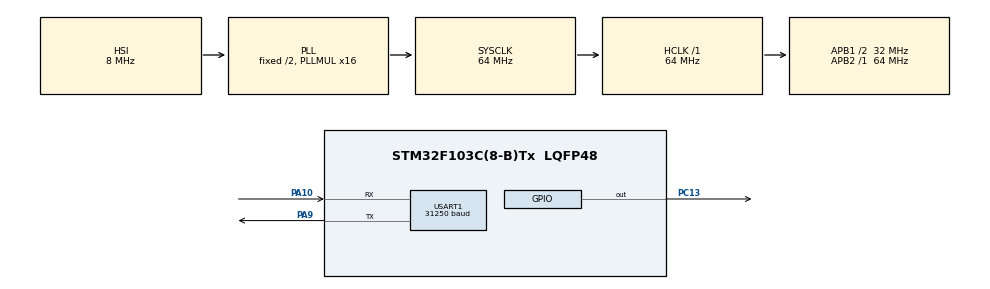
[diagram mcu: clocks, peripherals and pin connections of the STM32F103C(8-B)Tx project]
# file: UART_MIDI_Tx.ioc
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Mcu.Family=STM32F1
Mcu.Name=STM32F103C(8-B)Tx
Mcu.Package=LQFP48
NVIC.PriorityGroup=NVIC_PRIORITYGROUP_4
PA10.Mode=Asynchronous
PA10.Signal=USART1_RX
PA13.Mode=Serial_Wire
PA13.Signal=SYS_JTMS-SWDIO
PA14.Mode=Serial_Wire
PA14.Signal=SYS_JTCK-SWCLK
PA9.Mode=Asynchronous
PA9.Signal=USART1_TX
PC13-TAMPER-RTC.Signal=GPIO_Output
ProjectManager.HeapSize=0x200
ProjectManager.StackSize=0x400
ProjectManager.TargetToolchain=TrueSTUDIO
RCC.AHBFreq_Value=64000000
RCC.APB1CLKDivider=RCC_HCLK_DIV2
RCC.APB1Freq_Value=32000000
RCC.APB1TimFreq_Value=64000000
RCC.APB2Freq_Value=64000000
RCC.APB2TimFreq_Value=64000000
RCC.HCLKFreq_Value=64000000
RCC.PLLMUL=RCC_PLL_MUL16
RCC.SYSCLKFreq_VALUE=64000000
RCC.SYSCLKSource=RCC_SYSCLKSOURCE_PLLCLK
RCC.USBFreq_Value=64000000
USART1.BaudRate=31250
USART1.Mode=MODE_TX
USART1.VirtualMode=VM_ASYNC
board=custom

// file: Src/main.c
/* USER CODE BEGIN Header */
/**
  ******************************************************************************
  * @file           : main.c
  * @brief          : Main program body
  ******************************************************************************
  ** This notice applies to any and all portions of this file
  * that are not between comment pairs USER CODE BEGIN and
  * USER CODE END. Other portions of this file, whether
  * inserted by the user or by software development tools
  * are owned by their respective copyright owners.
  *
  * COPYRIGHT(c) 2019 STMicroelectronics
  *
  * Redistribution and use in source and binary forms, with or without modification,
  * are permitted provided that the following conditions are met:
  *   1. Redistributions of source code must retain the above copyright notice,
  *      this list of conditions and the following disclaimer.
  *   2. Redistributions in binary form must reproduce the above copyright notice,
  *      this list of conditions and the following disclaimer in the documentation
  *      and/or other materials provided with the distribution.
  *   3. Neither the name of STMicroelectronics nor the names of its contributors
  *      may be used to endorse or promote products derived from this software
  *      without specific prior written permission.
  *
  * THIS SOFTWARE IS PROVIDED BY THE COPYRIGHT HOLDERS AND CONTRIBUTORS "AS IS"
  * AND ANY EXPRESS OR IMPLIED WARRANTIES, INCLUDING, BUT NOT LIMITED TO, THE
  * IMPLIED WARRANTIES OF MERCHANTABILITY AND FITNESS FOR A PARTICULAR PURPOSE ARE
  * DISCLAIMED. IN NO EVENT SHALL THE COPYRIGHT HOLDER OR CONTRIBUTORS BE LIABLE
  * FOR ANY DIRECT, INDIRECT, INCIDENTAL, SPECIAL, EXEMPLARY, OR CONSEQUENTIAL
  * DAMAGES (INCLUDING, BUT NOT LIMITED TO, PROCUREMENT OF SUBSTITUTE GOODS OR
  * SERVICES; LOSS OF USE, DATA, OR PROFITS; OR BUSINESS INTERRUPTION) HOWEVER
  * CAUSED AND ON ANY THEORY OF LIABILITY, WHETHER IN CONTRACT, STRICT LIABILITY,
  * OR TORT (INCLUDING NEGLIGENCE OR OTHERWISE) ARISING IN ANY WAY OUT OF THE USE
  * OF THIS SOFTWARE, EVEN IF ADVISED OF THE POSSIBILITY OF SUCH DAMAGE.
  *
  ******************************************************************************
  */
/* USER CODE END Header */

#include "main.h"

UART_HandleTypeDef huart1;

void SystemClock_Config(void);
static void MX_GPIO_Init(void);
static void MX_USART1_UART_Init(void);

int main(void)
{

  /* MCU Configuration--------------------------------------------------------*/

  /* Reset of all peripherals, Initializes the Flash interface and the Systick. */
  HAL_Init();

  /* Configure the system clock */
  SystemClock_Config();

  /* Initialize all configured peripherals */
  MX_GPIO_Init();
  MX_USART1_UART_Init();
  /* USER CODE BEGIN 2 */
 	uint8_t nota_on[3];
 	nota_on[0] = 0b10010000;
 	nota_on[1] = 0;
 	nota_on[2] = 0;

 	uint8_t nota_off[3];
 	nota_off[0] = 0b00000000;
 	nota_off[1] = 0;
 	nota_off[2] = 0;

 	nota_on[1] = nota_on[1]+30;

// 	for(uint8_t i=1;i<89;i++){
// 		nota_on[1]= nota_on[1]+1;
// 		HAL_UART_Transmit(&huart1, nota_on, sizeof(nota_on), 10);
//		HAL_GPIO_TogglePin(GPIOC, GPIO_PIN_13);
//		HAL_Delay(500);
//		HAL_UART_Transmit(&huart1, nota_off, sizeof(nota_off), 10);
//		HAL_Delay(500);
// 	}
   /* USER CODE END 2 */

   /* Infinite loop */
   /* USER CODE BEGIN WHILE */
   while (1)
   {

HAL_UART_Transmit(&huart1, nota_on, sizeof(nota_on),1000);
HAL_GPIO_WritePin(GPIOC, GPIO_PIN_13, 1);
HAL_Delay(2000);
HAL_UART_Transmit(&huart1, nota_off, sizeof(nota_off),1000);
HAL_GPIO_WritePin(GPIOC, GPIO_PIN_13, 0);
HAL_Delay(2000);
 	// Tx un mensaje MIDI, note on, cada 2 segundos

     /* USER CODE END WHILE */

  }
}

void SystemClock_Config(void)
{
  RCC_OscInitTypeDef RCC_OscInitStruct = {0};
  RCC_ClkInitTypeDef RCC_ClkInitStruct = {0};

  /**Initializes the CPU, AHB and APB busses clocks
  */
  RCC_OscInitStruct.OscillatorType = RCC_OSCILLATORTYPE_HSI;
  RCC_OscInitStruct.HSIState = RCC_HSI_ON;
  RCC_OscInitStruct.HSICalibrationValue = RCC_HSICALIBRATION_DEFAULT;
  RCC_OscInitStruct.PLL.PLLState = RCC_PLL_ON;
  RCC_OscInitStruct.PLL.PLLSource = RCC_PLLSOURCE_HSI_DIV2;
  RCC_OscInitStruct.PLL.PLLMUL = RCC_PLL_MUL16;
  if (HAL_RCC_OscConfig(&RCC_OscInitStruct) != HAL_OK)
  {
    Error_Handler();
  }
  /**Initializes the CPU, AHB and APB busses clocks
  */
  RCC_ClkInitStruct.ClockType = RCC_CLOCKTYPE_HCLK|RCC_CLOCKTYPE_SYSCLK
                              |RCC_CLOCKTYPE_PCLK1|RCC_CLOCKTYPE_PCLK2;
  RCC_ClkInitStruct.SYSCLKSource = RCC_SYSCLKSOURCE_PLLCLK;
  RCC_ClkInitStruct.AHBCLKDivider = RCC_SYSCLK_DIV1;
  RCC_ClkInitStruct.APB1CLKDivider = RCC_HCLK_DIV2;
  RCC_ClkInitStruct.APB2CLKDivider = RCC_HCLK_DIV1;

  if (HAL_RCC_ClockConfig(&RCC_ClkInitStruct, FLASH_LATENCY_2) != HAL_OK)
  {
    Error_Handler();
  }
}

static void MX_USART1_UART_Init(void)
{

  huart1.Instance = USART1;
  huart1.Init.BaudRate = 31250;
  huart1.Init.WordLength = UART_WORDLENGTH_8B;
  huart1.Init.StopBits = UART_STOPBITS_1;
  huart1.Init.Parity = UART_PARITY_NONE;
  huart1.Init.Mode = UART_MODE_TX;
  huart1.Init.HwFlowCtl = UART_HWCONTROL_NONE;
  huart1.Init.OverSampling = UART_OVERSAMPLING_16;
  if (HAL_UART_Init(&huart1) != HAL_OK)
  {
    Error_Handler();
  }

}

static void MX_GPIO_Init(void)
{
  GPIO_InitTypeDef GPIO_InitStruct = {0};

  /* GPIO Ports Clock Enable */
  __HAL_RCC_GPIOC_CLK_ENABLE();
  __HAL_RCC_GPIOA_CLK_ENABLE();

  /*Configure GPIO pin Output Level */
  HAL_GPIO_WritePin(GPIOC, GPIO_PIN_13, GPIO_PIN_RESET);

  /*Configure GPIO pin : PC13 */
  GPIO_InitStruct.Pin = GPIO_PIN_13;
  GPIO_InitStruct.Mode = GPIO_MODE_OUTPUT_PP;
  GPIO_InitStruct.Pull = GPIO_NOPULL;
  GPIO_InitStruct.Speed = GPIO_SPEED_FREQ_LOW;
  HAL_GPIO_Init(GPIOC, &GPIO_InitStruct);

}

void Error_Handler(void)
{
}

/************************ (C) COPYRIGHT STMicroelectronics *****END OF FILE****/
